# DA14683 register map
Vendor: Dialog; Series: DA14683; File version: 1.2
CPU: CM0 r1p0, little endian, MPU, FPU, 3 interrupt priority bits
Registers are 16-bit, read-write, reset 0x0 unless marked. A register's access mark holds for its fields unless they carry their own. Offsets are from the block's base; [hi:lo] are bit positions.

## WAKEUP — WAKEUP registers
Base 0x50000100
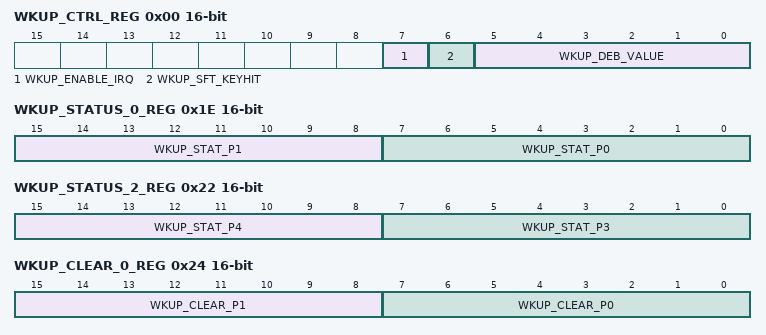
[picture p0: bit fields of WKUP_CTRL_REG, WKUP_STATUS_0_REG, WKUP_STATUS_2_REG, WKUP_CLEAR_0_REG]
0x00 WKUP_CTRL_REG — Control register for the wakeup counter
  [7] WKUP_ENABLE_IRQ — 0: no interrupt will be enabled 1: if you have an event an IRQ will be generated
  [6] WKUP_SFT_KEYHIT — 0 = no effect 1 = emulate key hit. First make this bit 0 before any new key hit can be sensed.
  [5:0] WKUP_DEB_VALUE — Wakeup debounce time. If set to 0, no debouncing will be done. Debounce time: N*1 ms. N =1..63
0x04 WKUP_RESET_IRQ_REG — Reset wakeup interrupt
  [15:0] WKUP_IRQ_RST wo — writing any value to this register will reset the interrupt. reading always returns 0.
0x0A WKUP_SELECT_P0_REG — select which inputs from P0 port can trigger wkup counter
  [7:0] WKUP_SELECT_P0 — 0: input P0x is not enabled for wakeup event 1: input P0x is enabled for wakeup event
0x0C WKUP_SELECT_P1_REG — select which inputs from P1 port can trigger wkup counter
  [7:0] WKUP_SELECT_P1 — 0: input P1x is not enabled for wakeup event 1: input P1x is enabled for wakeup event
0x0E WKUP_SELECT_P2_REG — select which inputs from P2 port can trigger wkup counter
  [4:0] WKUP_SELECT_P2 — 0: input P2x is not enabled for wakeup event 1: input P2x is enabled for wakeup event
0x10 WKUP_SELECT_P3_REG — select which inputs from P3 port can trigger wkup counter
  [7:0] WKUP_SELECT_P3 — 0: input P3x is not enabled for wakeup event 1: input P3x is enabled for wakeup event
0x12 WKUP_SELECT_P4_REG — select which inputs from P3 port can trigger wkup counter
  [7:0] WKUP_SELECT_P4 — 0: input P4x is not enabled for wakeup event 1: input P4x is enabled for wakeup event
0x14 WKUP_POL_P0_REG — select the sesitivity polarity for each P0 input
  [7:0] WKUP_POL_P0 — 0: enabled input P0x will give an event if that input goes high 1: enabled input P0x will give an event if that input goes low
0x16 WKUP_POL_P1_REG — select the sesitivity polarity for each P1 input
  [7:0] WKUP_POL_P1 — 0: enabled input P1x will give an event if that input goes high 1: enabled input P1x will give an event if that input goes low
0x18 WKUP_POL_P2_REG — select the sesitivity polarity for each P2 input
  [4:0] WKUP_POL_P2 — 0: enabled input P2x will give an event if that input goes high 1: enabled input P2x will give an event if that input goes low
0x1A WKUP_POL_P3_REG — select the sesitivity polarity for each P3 input
  [7:0] WKUP_POL_P3 — 0: enabled input P3x will give an event if that input goes high 1: enabled input P3x will give an event if that input goes low
0x1C WKUP_POL_P4_REG — select the sesitivity polarity for each P3 input
  [7:0] WKUP_POL_P4 — 0: enabled input P4x will give an event if that input goes high 1: enabled input P4x will give an event if that input goes low
0x1E WKUP_STATUS_0_REG — Event status register for P0 and P1
  [15:8] WKUP_STAT_P1 ro — Contains the latched value of any toggle of the GPIOs Port P1. WKUP_STAT_P0[8] -> P1_0.
  [7:0] WKUP_STAT_P0 ro — Contains the latched value of any toggle of the GPIOs Port P0. WKUP_STAT_P0[0] -> P0_0.
0x20 WKUP_STATUS_1_REG — Event status register for P2
  [4:0] WKUP_STAT_P2 ro — Contains the latched value of any toggle of the GPIOs Port P2 WKUP_STATUS_1[0] -> P2_0.
0x22 WKUP_STATUS_2_REG — Event status register for P3 and P4
  [15:8] WKUP_STAT_P4 ro — Contains the latched value of any toggle of the GPIOs Port P4. WKUP_STATUS_2[8] -> P4_0.
  [7:0] WKUP_STAT_P3 ro — Contains the latched value of any toggle of the GPIOs Port P3. WKUP_STATUS_2[0] -> P3_0.
0x24 WKUP_CLEAR_0_REG — Clear event register for P0 and P1
  [15:8] WKUP_CLEAR_P1 wo — Clear latched value of the GPIOs P1 when corresponding bit is 1
  [7:0] WKUP_CLEAR_P0 wo — Clear latched value of the GPIOs P0 when corresponding bit is 1
0x26 WKUP_CLEAR_1_REG — Clear event register for P2
  [4:0] WKUP_CLEAR_P2 wo — Clear latched value of the GPIOs P2 when corresponding bit is 1
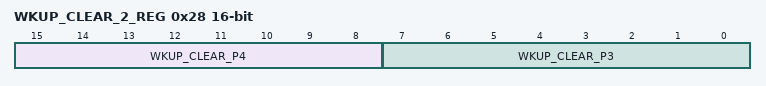
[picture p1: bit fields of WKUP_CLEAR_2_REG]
0x28 WKUP_CLEAR_2_REG — Clear event register for P3 and P4
  [15:8] WKUP_CLEAR_P4 wo — Clear latched value of the GPIOs P4 when corresponding bit is 1
  [7:0] WKUP_CLEAR_P3 wo — Clear latched value of the GPIOs P3 when corresponding bit is 1
0x2A WKUP_SEL_GPIO_P0_REG — select which inputs from P0 port can trigger interrupt
  [7:0] WKUP_SEL_GPIO_P0 — 0: input P0x is not enabled for GPIO interrupt 1: input P0x is enabled for GPIO interrupt
0x2C WKUP_SEL_GPIO_P1_REG — select which inputs from P1 port can trigger interrupt
  [7:0] WKUP_SEL_GPIO_P1 — 0: input P1x is not enabled for GPIO interrupt 1: input P1x is enabled for GPIO interrupt
0x2E WKUP_SEL_GPIO_P2_REG — select which inputs from P2 port can trigger interrupt
  [4:0] WKUP_SEL_GPIO_P2 — 0: input P2x is not enabled for GPIO interrupt 1: input P2x is enabled for GPIO interrupt
0x30 WKUP_SEL_GPIO_P3_REG — select which inputs from P3 port can trigger interrupt
  [7:0] WKUP_SEL_GPIO_P3 — 0: input P3x is not enabled for GPIO interrupt 1: input P3x is enabled for GPIO interrupt
0x32 WKUP_SEL_GPIO_P4_REG — select which inputs from P3 port can trigger interrupt
  [7:0] WKUP_SEL_GPIO_P4 — 0: input P4x is not enabled for GPIO interrupt 1: input P4x is enabled for GPIO interrupt
